# AE822FA0E5597LS0_CM55_HP_View register map
Vendor: Alif Semiconductor; Series: E8; File version: 1.0
CPU: CM55 r1p0, selectable endian, MPU, FPU, double-precision FPU, DSP, VTOR, 8 interrupt priority bits, 1 SAU regions
Registers are 32-bit, read-write, reset 0x0 unless marked. A register's access mark holds for its fields unless they carry their own. Offsets are from the block's base; [hi:lo] are bit positions; {n}, {i} and the like mark numbered series.

## JPEG
Base 0x49044000
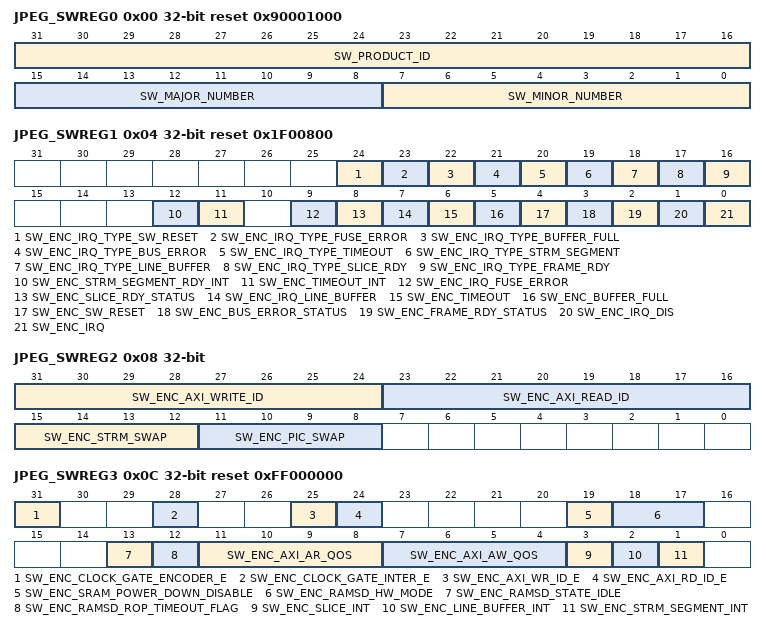
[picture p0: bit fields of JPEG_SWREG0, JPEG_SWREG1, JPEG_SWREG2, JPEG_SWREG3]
0x00 JPEG_SWREG0 ro reset 0x90001000 — ID register (read only)
  [31:16] SW_PRODUCT_ID — Product ID
  [15:8] SW_MAJOR_NUMBER — Major number
  [7:0] SW_MINOR_NUMBER — Minor number
0x04 JPEG_SWREG1 reset 0x1F00800 — Interrupt register encoder
  [24] SW_ENC_IRQ_TYPE_SW_RESET — IRQ type SW reset mask. 0=normal interruption. 1=abnormal interruption
  [23] SW_ENC_IRQ_TYPE_FUSE_ERROR — IRQ type fuse error mask. 0=normal interruption. 1=abnormal interruption
  [22] SW_ENC_IRQ_TYPE_BUFFER_FULL — IRQ type fuse buffer full mask. 0=normal interruption. 1=abnormal interruption
  [21] SW_ENC_IRQ_TYPE_BUS_ERROR — IRQ type bus error mask. 0=normal interruption. 1=abnormal interruption
  [20] SW_ENC_IRQ_TYPE_TIMEOUT — IRQ type timeout mask. 0=normal interruption. 1=abnormal interruption
  [19] SW_ENC_IRQ_TYPE_STRM_SEGMENT — IRQ type stream segment mask. 0=normal interruption. 1=abnormal interruption.
  [18] SW_ENC_IRQ_TYPE_LINE_BUFFER — IRQ type line buffer mask. 0=normal interruption. 1=abnormal interruption.
  [17] SW_ENC_IRQ_TYPE_SLICE_RDY — IRQ type slice ready mask. 0=normal interruption. 1=abnormal interruption.
  [16] SW_ENC_IRQ_TYPE_FRAME_RDY — IRQ type frame ready mask. 0=normal interruption. 1=abnormal interruption.
  [12] SW_ENC_STRM_SEGMENT_RDY_INT — Output stream segment IRQ. When high stream segment requests an interrupt. SW will reset this after interrupt is handled. It is clear by writing 1.
  [11] SW_ENC_TIMEOUT_INT — Enable timeout interrupt when 1
  [9] SW_ENC_IRQ_FUSE_ERROR — Interrupt status bit encoder. When this bit is high encoder has a FUSE error. SW try to setup feature but HW miss the feature set. It is clear by writing 1.
  [8] SW_ENC_SLICE_RDY_STATUS — Interrupt status bit encoder. When this bit is high encoder has encoded a slice. It is clear by writing 1.
  [7] SW_ENC_IRQ_LINE_BUFFER — Interrupt status bit encoder line buffer empty. When setting. Encoder has finished encoding input buffers. It is clear by writing 1.
  [6] SW_ENC_TIMEOUT — Interrupt status bit encoder timeout. When high the encoder has been idling for too long. Possible only if timeout interrupt is enabled. It is clear by writing 1.
  [5] SW_ENC_BUFFER_FULL — IRQ buffer full status bit. bufferFullInterrupt. It is clear by writing 1.
  [4] SW_ENC_SW_RESET — IRQ SW reset status bit. It is clear by writing 1.
  [3] SW_ENC_BUS_ERROR_STATUS — Interrupt status bit bus. Error response from bus. It is clear by writing 1.
  [2] SW_ENC_FRAME_RDY_STATUS — Interrupt status bit encoder. When this bit is high encoder has encoded a picture. It is clear by writing 1.
  [1] SW_ENC_IRQ_DIS — Encoder IRQ disable. When high there are no interrupts concerning encoder from HW. Polling must be used to see the interrupt statuses.
  [0] SW_ENC_IRQ — Encoder IRQ. When high encoder requests an interrupt. SW will reset this after interrupt is handled. It is clear by writing 1.
0x08 JPEG_SWREG2 — Data configuration register 0
  [31:24] SW_ENC_AXI_WRITE_ID — AXI Write ID
  [23:16] SW_ENC_AXI_READ_ID — AXI Read ID
  [15:12] SW_ENC_STRM_SWAP — Byte swap config for output stream data. 4-bit byte order vector to control byte locations inside HW internal 128 bit data vector. For 64 and 32 bit external bus widths the data is first gathered to 128 bit width and then bytes swapped accordingly.
  [11:8] SW_ENC_PIC_SWAP — Byte swap configuration for picture data (encoder input)
0x0C JPEG_SWREG3 reset 0xFF000000 — Data configuration register 1
  [31] SW_ENC_CLOCK_GATE_ENCODER_E — ASIC encoder clock gating control. 0=clock always on. 1=hardware clock gating control
  [28] SW_ENC_CLOCK_GATE_INTER_E — ASIC inter clock gating control. 0=clock always on. 1=hardware clock gating control
  [25] SW_ENC_AXI_WR_ID_E — AXI write enable. 0=disable. 1=enable.
  [24] SW_ENC_AXI_RD_ID_E — AXI read enable. 0=disable. 1=enable.
  [19] SW_ENC_SRAM_POWER_DOWN_DISABLE — SRAM power down mode disable
    1=SRAM power always on; 0=Go into power down mode when clock is gated
  [18:17] SW_ENC_RAMSD_HW_MODE — SRAM SD HW controlled mode
  [13] SW_ENC_RAMSD_STATE_IDLE ro — SRAM SD process idle state. 0=some srams are in the sd process. 1=all sram have completed sd process
  [12] SW_ENC_RAMSD_ROP_TIMEOUT_FLAG — Flags the timeout status of the sram SD_ROP signal. 0=the sram SD_ROP signal has not timed out. 1=the sram SD_ROP signal has timed out
  [11:8] SW_ENC_AXI_AR_QOS — AXI QoS identifier sent on the read address channel for read transaction
  [7:4] SW_ENC_AXI_AW_QOS — AXI QoS identifier sent on the write address channel for write transaction
  [3] SW_ENC_SLICE_INT — Enable slice interrupt when 1
  [2] SW_ENC_LINE_BUFFER_INT — Enable line buffer interrupt when 1
  [1] SW_ENC_STRM_SEGMENT_INT — Enable stream segment interrupt when 1
0x10 JPEG_SWREG4 — Control register 0
  [31:29] SW_ENC_MODE — Encoding mode. streamType. 3=AV1. 4=JPEG. Others=Reserved.
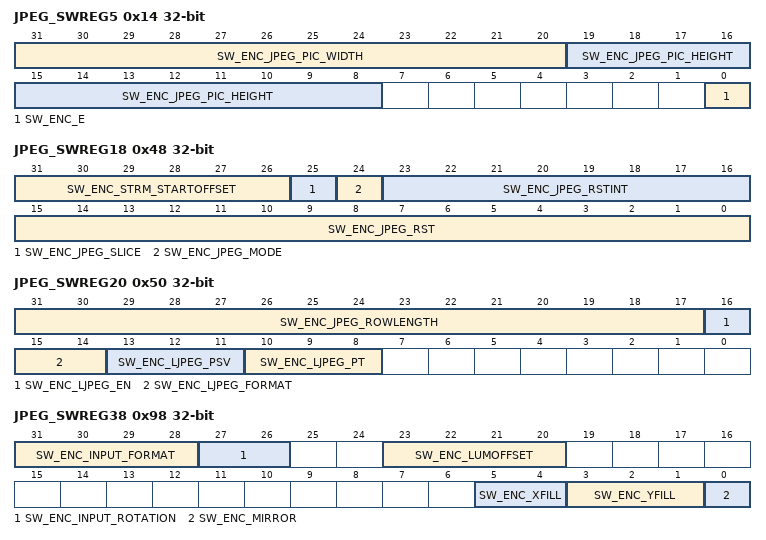
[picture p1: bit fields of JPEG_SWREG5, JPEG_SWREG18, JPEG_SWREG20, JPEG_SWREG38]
0x14 JPEG_SWREG5 — Control register 1
  [31:20] SW_ENC_JPEG_PIC_WIDTH — Encoded JPEG width. jpgLumWidth(unit 8 pixels)
  [19:8] SW_ENC_JPEG_PIC_HEIGHT — Encoded JPEG height. jpgLumHeight(unit 8 pixels): Max width x height is 16384 x 16384
  [0] SW_ENC_E — Encoder enable. Setting this bit high will start the encoding operation. HW will reset this when picture is processed or bus error or timeout interrupt is given.
0x20 JPEG_SWREG8 — Stream output buffer 0 address
  [31:0] SW_ENC_OUTPUT_STRM_BASE — stream output buffer0 base address
0x24 JPEG_SWREG9 — Stream output buffer 0 limit size
  [31:0] SW_ENC_OUTPUT_STRM_BUFFER_LIMIT — Stream buffer0 limit / Output stream size (bytes). If buffer0 limit is reached and sw_enc_HWStreamBufChain=0, buffer_full_IRQ will be generated. Output stream size will be updated here when a slice or frame is finished.
0x30 JPEG_SWREG12 — Input luma base address
  [31:0] SW_ENC_INPUT_Y_BASE — Input image luma base address
0x34 JPEG_SWREG13 — Input Cb base address
  [31:0] SW_ENC_INPUT_CB_BASE — Input image Cb base address
0x38 JPEG_SWREG14 — Input Cr base address
  [31:0] SW_ENC_INPUT_CR_BASE — Input image Cr base address
0x48 JPEG_SWREG18 — Reference picture reconstructed list 0 luma 0
  [31:26] SW_ENC_STRM_STARTOFFSET — Stream start offset = amount of StrmHdrRem (bits) [0..63]
  [25] SW_ENC_JPEG_SLICE — JPEG slice enable. 0=picture ends with EOI. 1=slice ends with RST
  [24] SW_ENC_JPEG_MODE — JPEG mode. 0=4:2:0 (4lum+2chr blocks/MCU). 1=4:2:2 (2lum+2chr blocks/MCU).
  [23:16] SW_ENC_JPEG_RSTINT — JPEG restart marker interval when slices are disabled (mb rows) [0..255]
  [15:0] SW_ENC_JPEG_RST — JPEG restart marker for first RST. incremented by HW for next RST
0x4C JPEG_SWREG19 — Reference picture reconstructed list 0 chroma 0
  [31:0] SW_ENC_STRM_HDRREM1 — Stream header remainder bits MSB (MSB aligned)
0x50 JPEG_SWREG20 — Reference picture reconstructed list 0 luma 1
  [31:17] SW_ENC_JPEG_ROWLENGTH — JPEG Input luminance row length. jpgLumWidthSrc (pixels) [96..16384]
  [16] SW_ENC_LJPEG_EN — JPEG enable lossless JPEG with Huffman coding
  [15:14] SW_ENC_LJPEG_FORMAT — JPEG Coding Mode. 0=420. 1=422. 2=luma only.
  [13:11] SW_ENC_LJPEG_PSV — JPEG prediction selection value for lossless
  [10:8] SW_ENC_LJPEG_PT — JPEG point transform value for lossless
0x54 JPEG_SWREG21 — Reference picture reconstructed list 0 chroma 1
  [31:0] SW_ENC_STRM_HDRREM2 — Stream header remainder bits LSB (MSB aligned)
0x94 JPEG_SWREG37 — SAO lambda parameter
  [3:0] SW_ENC_CHROFFSET — Input chrominance offset (bytes) [0..15]
0x98 JPEG_SWREG38 — Pre-processor configuration
  [31:28] SW_ENC_INPUT_FORMAT — Input image format. inputFormat. 0=YUV420P. 1=YUV420SP. 2=YUYV422. 3=UYVY422. Others=Reserved.
  [27:26] SW_ENC_INPUT_ROTATION — Input image rotation. 0=disabled. Others=Reserved.
  [23:20] SW_ENC_LUMOFFSET — Input luminance offset (bytes) [0..15]
  [5:4] SW_ENC_XFILL — Overfill pixels on right edge of image div2 [0.1.2.3]
  [3:1] SW_ENC_YFILL — Overfill pixels on bottom edge of image. YFill. [0...7]
  [0] SW_ENC_MIRROR — Mirror or not. [0.1]
0xB0 JPEG_SWREG44 — Pre-processor down-scaled configuration 1
  [1:0] SW_ENC_INPUT_FORMAT_MSB — Input image format bit[5:4]. inputFormatMsb.
0xB4 JPEG_SWREG45 — Pre-processor down-scaled configuration 2
  [27] SW_ENC_CHROMA_SWAP — Swap order of chroma bytes in semi planar input format.
0xD4 JPEG_SWREG53 — Input luma base address MSB
  [31:0] SW_ENC_INPUT_Y_BASE_MSB
0xD8 JPEG_SWREG54 — Input Cb base address MSB
  [31:0] SW_ENC_INPUT_CB_BASE_MSB
0xDC JPEG_SWREG55 — Input Cr base address MSB
  [31:0] SW_ENC_INPUT_CR_BASE_MSB
0xEC JPEG_SWREG59 — Stream output buffer 0 address MSB
  [31:0] SW_ENC_OUTPUT_STRM_BASE_MSB — Stream output buffer0 address MSB
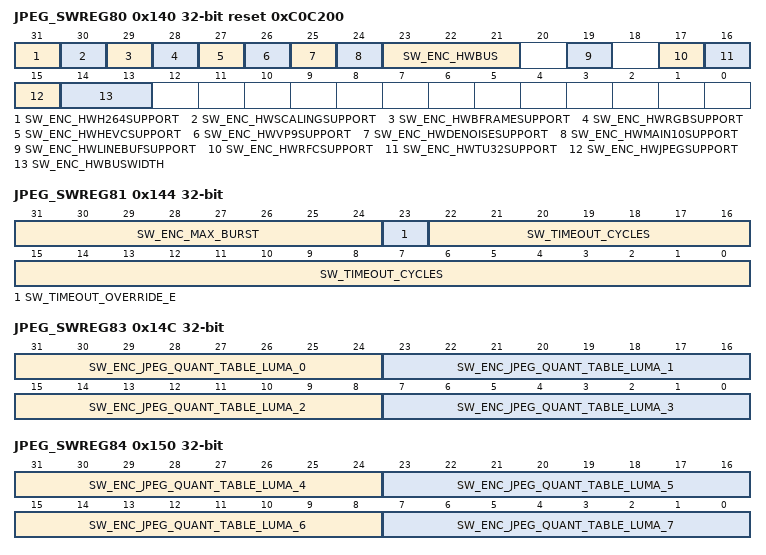
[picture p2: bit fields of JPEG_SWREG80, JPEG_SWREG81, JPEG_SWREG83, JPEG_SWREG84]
0x140 JPEG_SWREG80 ro reset 0xC0C200 — HW synthesis configuration register, read-only
  [31] SW_ENC_HWH264SUPPORT — H264 encoding supported by HW. 0=not supported.
  [30] SW_ENC_HWSCALINGSUPPORT — Down-scaling supported by HW. 0=not supported.
  [29] SW_ENC_HWBFRAMESUPPORT — HW bframe support. 0=not support bframe.
  [28] SW_ENC_HWRGBSUPPORT — RGB to YUV conversion supported by HW. 0=not supported.
  [27] SW_ENC_HWHEVCSUPPORT — HEVC encoding supported by HW. 0=not supported.
  [26] SW_ENC_HWVP9SUPPORT — VP9 encoding supported by HW. 0=not supported.
  [25] SW_ENC_HWDENOISESUPPORT — Denoise supported by HW. 0=not supported.
  [24] SW_ENC_HWMAIN10SUPPORT — Main profile supported by HW. 0=Main8 supported.
  [23:21] SW_ENC_HWBUS — Bus connection of HW. 6=AXIAPB.
  [19] SW_ENC_HWLINEBUFSUPPORT — LineBuffer input mode supported by HW. 0=not supported.
  [17] SW_ENC_HWRFCSUPPORT — Reference frame compression supported by HW. 0=not supported.
  [16] SW_ENC_HWTU32SUPPORT — TU32 supported by HW. 0=not supported.
  [15] SW_ENC_HWJPEGSUPPORT — JPEG encoder supported by HW.1=supported
  [14:13] SW_ENC_HWBUSWIDTH — Bus width of HW. 2=128b
0x144 JPEG_SWREG81 — Hardware configuration 0
  [31:24] SW_ENC_MAX_BURST — Maximum AXI burst length. Default value: 0x10
  [23] SW_TIMEOUT_OVERRIDE_E — Enable signal if timeout period is controlled by software. Default value: 0x0
  [22:0] SW_TIMEOUT_CYCLES — Timeout cycles number. Default value: 0x0
0x148 JPEG_SWREG82 — Record hardware performance
  [31:0] SW_ENC_HW_PERFORMANCE — Record hardware performance (cycles) of current picture
0x14C JPEG_SWREG83 — Reference picture reconstructed list 1 luma 0
  [31-8n:24-8n] SW_ENC_JPEG_QUANT_TABLE_LUMA_{n} (n=0..3) — JPEG quant table luma entry {n}
0x150 JPEG_SWREG84 — Reference picture reconstructed list 1 chroma 0
  [63-8n:56-8n] SW_ENC_JPEG_QUANT_TABLE_LUMA_{n} (n=4..7) — JPEG quant table luma entry {n}
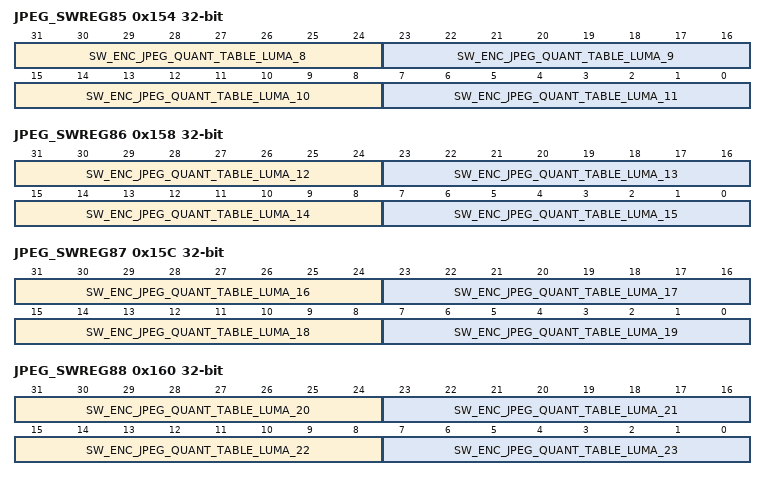
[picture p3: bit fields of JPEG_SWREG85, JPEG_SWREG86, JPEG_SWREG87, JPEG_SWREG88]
0x154 JPEG_SWREG85 — Reference picture reconstructed list 1 luma 1
  [95-8n:88-8n] SW_ENC_JPEG_QUANT_TABLE_LUMA_{n} (n=8..11) — JPEG quant table luma entry {n}
0x158 JPEG_SWREG86 — Reference picture reconstructed list 1 chroma 1
  [127-8n:120-8n] SW_ENC_JPEG_QUANT_TABLE_LUMA_{n} (n=12..15) — JPEG quant table luma entry {n}
0x15C JPEG_SWREG87 — Reference picture reconstructed list 1 luma 0 MSB
  [159-8n:152-8n] SW_ENC_JPEG_QUANT_TABLE_LUMA_{n} (n=16..19) — JPEG quant table luma entry {n}
0x160 JPEG_SWREG88 — Reference picture reconstructed list 1 chroma 0 MSB
  [191-8n:184-8n] SW_ENC_JPEG_QUANT_TABLE_LUMA_{n} (n=20..23) — JPEG quant table luma entry {n}
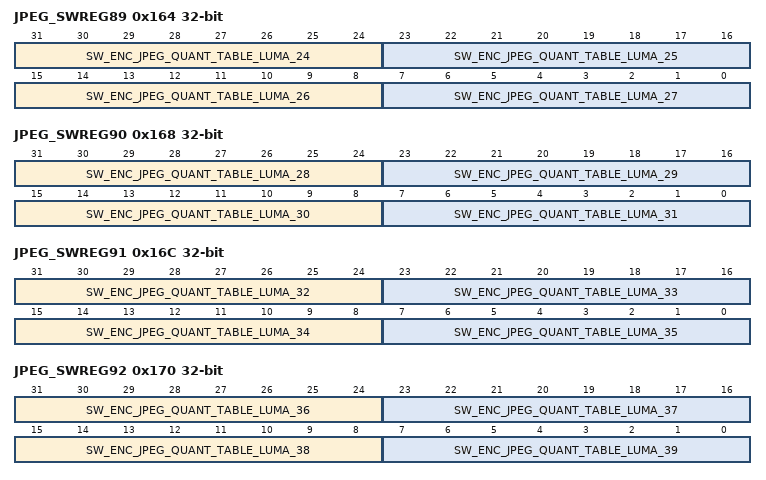
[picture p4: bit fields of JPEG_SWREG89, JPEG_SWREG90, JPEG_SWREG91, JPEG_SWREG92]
0x164 JPEG_SWREG89 — Reference picture reconstructed list 1 luma 1 MSB
  [223-8n:216-8n] SW_ENC_JPEG_QUANT_TABLE_LUMA_{n} (n=24..27) — JPEG quant table luma entry {n}
0x168 JPEG_SWREG90 — Reference picture reconstructed list 1 chroma 1 MSB
  [255-8n:248-8n] SW_ENC_JPEG_QUANT_TABLE_LUMA_{n} (n=28..31) — JPEG quant table luma entry {n}
0x16C JPEG_SWREG91 — Reference pictures list 1 configuration
  [287-8n:280-8n] SW_ENC_JPEG_QUANT_TABLE_LUMA_{n} (n=32..35) — JPEG quant table luma entry {n}
0x170 JPEG_SWREG92 — Reference picture reconstructed list 1 4n 0
  [319-8n:312-8n] SW_ENC_JPEG_QUANT_TABLE_LUMA_{n} (n=36..39) — JPEG quant table luma entry {n}
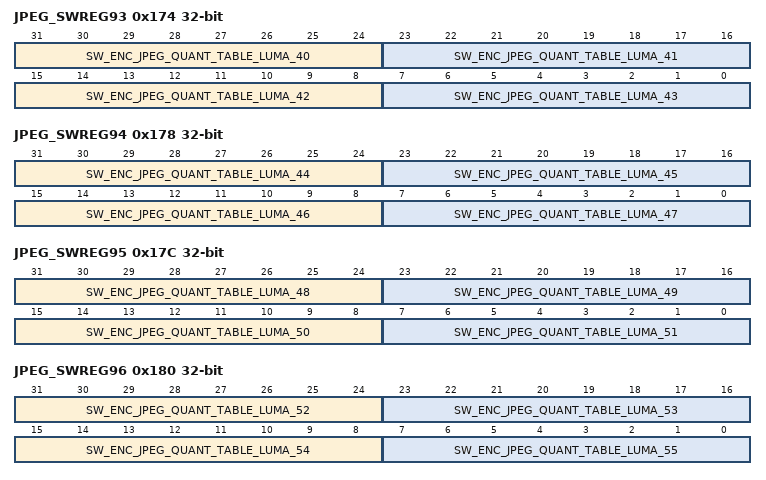
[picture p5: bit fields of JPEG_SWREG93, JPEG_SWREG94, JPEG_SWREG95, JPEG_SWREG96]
0x174 JPEG_SWREG93 — Reference picture reconstructed list 1 4n 0 MSB
  [351-8n:344-8n] SW_ENC_JPEG_QUANT_TABLE_LUMA_{n} (n=40..43) — JPEG quant table luma entry {n}
0x178 JPEG_SWREG94 — Reference picture reconstructed list 1 4n 1
  [383-8n:376-8n] SW_ENC_JPEG_QUANT_TABLE_LUMA_{n} (n=44..47) — JPEG quant table luma entry {n}
0x17C JPEG_SWREG95 — Reference picture reconstructed list 1 4n 1 MSB
  [415-8n:408-8n] SW_ENC_JPEG_QUANT_TABLE_LUMA_{n} (n=48..51) — JPEG quant table luma entry {n}
0x180 JPEG_SWREG96 — Base address for list 1 ref 0 luma compress table LSB
  [447-8n:440-8n] SW_ENC_JPEG_QUANT_TABLE_LUMA_{n} (n=52..55) — JPEG quant table luma entry {n}
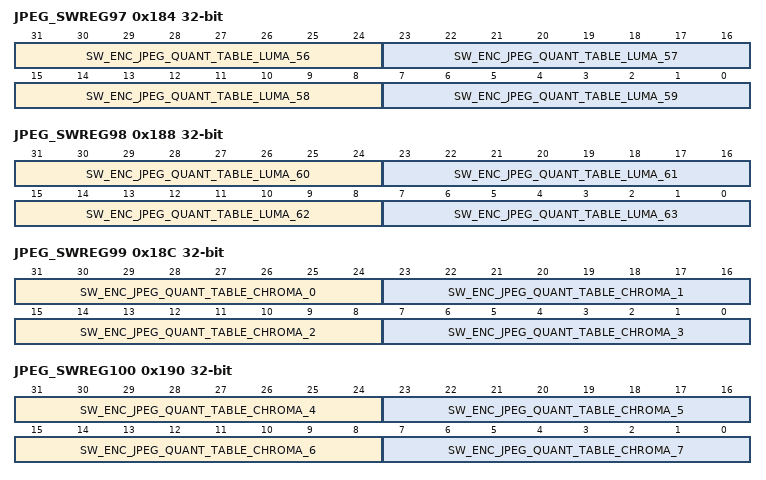
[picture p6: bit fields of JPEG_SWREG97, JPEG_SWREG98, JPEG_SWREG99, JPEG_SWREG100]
0x184 JPEG_SWREG97 — Base address for list 1 ref 0 luma compress table MSB
  [479-8n:472-8n] SW_ENC_JPEG_QUANT_TABLE_LUMA_{n} (n=56..59) — JPEG quant table luma entry {n}
0x188 JPEG_SWREG98 — Base address for list 1 ref 0 chroma compress table LSB
  [511-8n:504-8n] SW_ENC_JPEG_QUANT_TABLE_LUMA_{n} (n=60..63) — JPEG quant table luma entry {n}
0x18C JPEG_SWREG99 — Base address for list 1 ref 0 chroma compress table MSB
  [31-8n:24-8n] SW_ENC_JPEG_QUANT_TABLE_CHROMA_{n} (n=0..3) — JPEG quant table chroma entry {n}
0x190 JPEG_SWREG100 — Base address for list 1 ref 1 luma compress table LSB
  [63-8n:56-8n] SW_ENC_JPEG_QUANT_TABLE_CHROMA_{n} (n=4..7) — JPEG quant table chroma entry {n}
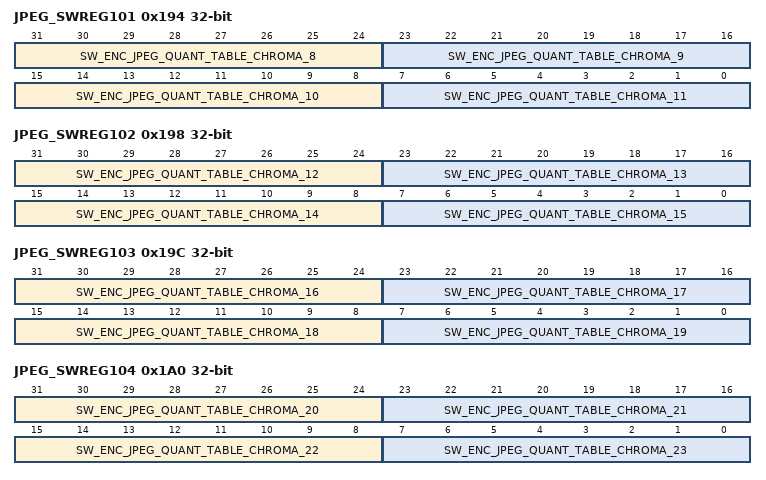
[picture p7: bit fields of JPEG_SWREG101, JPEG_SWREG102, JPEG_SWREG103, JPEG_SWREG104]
0x194 JPEG_SWREG101 — Base address for list 1 ref 1 luma compress table MSB
  [95-8n:88-8n] SW_ENC_JPEG_QUANT_TABLE_CHROMA_{n} (n=8..11) — JPEG quant table chroma entry {n}
0x198 JPEG_SWREG102 — Base address for list 1 ref 1 chroma compress table LSB
  [127-8n:120-8n] SW_ENC_JPEG_QUANT_TABLE_CHROMA_{n} (n=12..15) — JPEG quant table chroma entry {n}
0x19C JPEG_SWREG103 — Base address for list 1 ref 1 chroma compress table MSB
  [159-8n:152-8n] SW_ENC_JPEG_QUANT_TABLE_CHROMA_{n} (n=16..19) — JPEG quant table chroma entry {n}
0x1A0 JPEG_SWREG104 — Reference picture lists modification
  [191-8n:184-8n] SW_ENC_JPEG_QUANT_TABLE_CHROMA_{n} (n=20..23) — JPEG quant table chroma entry {n}
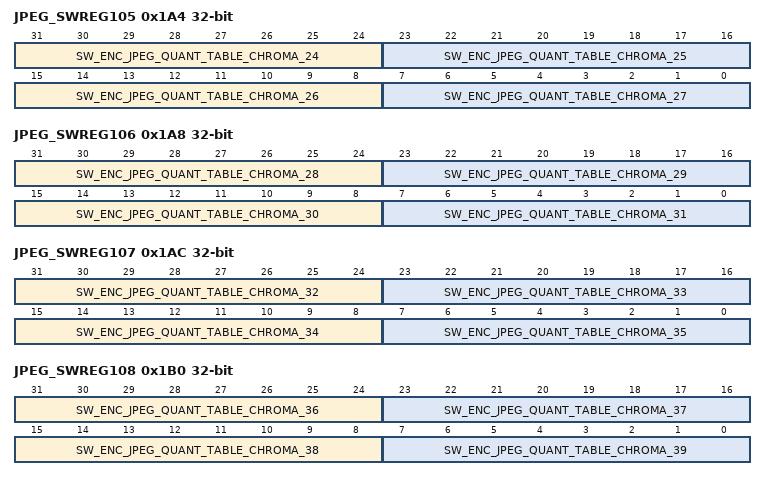
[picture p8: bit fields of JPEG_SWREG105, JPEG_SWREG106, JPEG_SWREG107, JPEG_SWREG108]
0x1A4 JPEG_SWREG105 — Target picture size
  [223-8n:216-8n] SW_ENC_JPEG_QUANT_TABLE_CHROMA_{n} (n=24..27) — JPEG quant table chroma entry {n}
0x1A8 JPEG_SWREG106 — Min picture size
  [255-8n:248-8n] SW_ENC_JPEG_QUANT_TABLE_CHROMA_{n} (n=28..31) — JPEG quant table chroma entry {n}
0x1AC JPEG_SWREG107 — Max picture size
  [287-8n:280-8n] SW_ENC_JPEG_QUANT_TABLE_CHROMA_{n} (n=32..35) — JPEG quant table chroma entry {n}
0x1B0 JPEG_SWREG108 — Average QP
  [319-8n:312-8n] SW_ENC_JPEG_QUANT_TABLE_CHROMA_{n} (n=36..39) — JPEG quant table chroma entry {n}
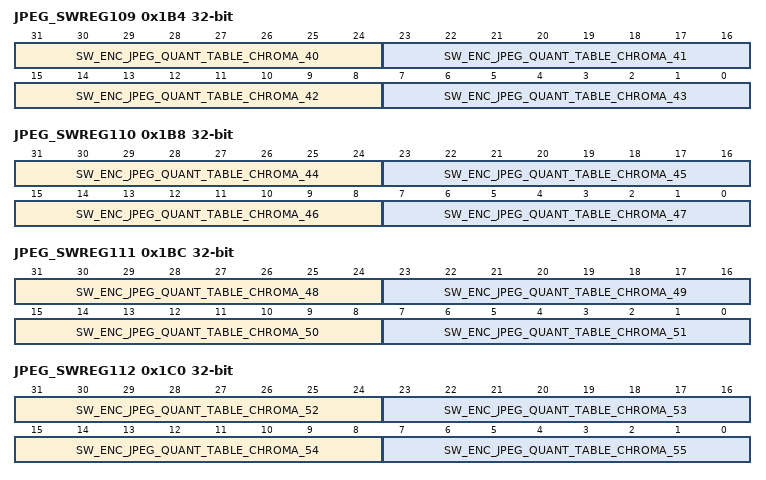
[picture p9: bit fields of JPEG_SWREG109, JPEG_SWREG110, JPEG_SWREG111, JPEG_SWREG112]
0x1B4 JPEG_SWREG109 — QP delta map
  [351-8n:344-8n] SW_ENC_JPEG_QUANT_TABLE_CHROMA_{n} (n=40..43) — JPEG quant table chroma entry {n}
0x1B8 JPEG_SWREG110 — QP delta map MSB
  [383-8n:376-8n] SW_ENC_JPEG_QUANT_TABLE_CHROMA_{n} (n=44..47) — JPEG quant table chroma entry {n}
0x1BC JPEG_SWREG111 — Adaptive GOP configuration 1
  [415-8n:408-8n] SW_ENC_JPEG_QUANT_TABLE_CHROMA_{n} (n=48..51) — JPEG quant table chroma entry {n}
0x1C0 JPEG_SWREG112 — Adaptive GOP configuration 2
  [447-8n:440-8n] SW_ENC_JPEG_QUANT_TABLE_CHROMA_{n} (n=52..55) — JPEG quant table chroma entry {n}
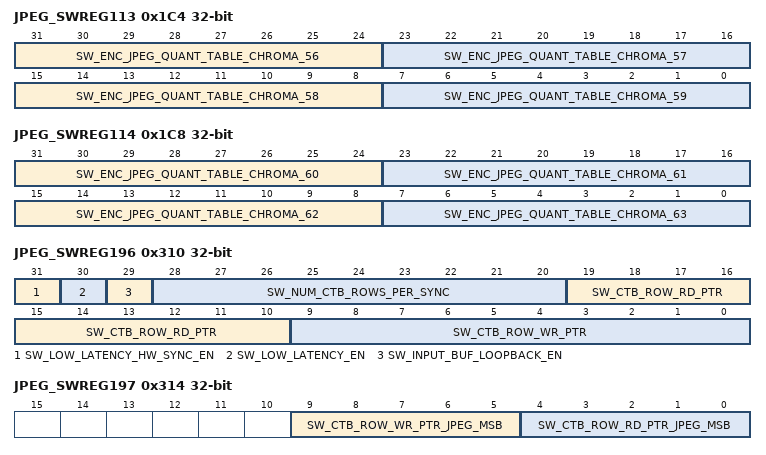
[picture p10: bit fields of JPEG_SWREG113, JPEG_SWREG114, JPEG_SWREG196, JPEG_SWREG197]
0x1C4 JPEG_SWREG113 — Adaptive GOP configuration 3
  [479-8n:472-8n] SW_ENC_JPEG_QUANT_TABLE_CHROMA_{n} (n=56..59) — JPEG quant table chroma entry {n}
0x1C8 JPEG_SWREG114 — CTB rate control bit memory address of current frame
  [511-8n:504-8n] SW_ENC_JPEG_QUANT_TABLE_CHROMA_{n} (n=60..63) — JPEG quant table chroma entry {n}
0x1FC JPEG_SWREG127 — Overlay 1 input luma buffer address
  [31:0] SW_ENC_OVERLAY_INPUT_YADDR1 — Overlay 1 input luma buffer address / OSDMap input buffer address
0x200 JPEG_SWREG128 — Overlay 1 input luma buffer address MSB part
  [31:0] SW_ENC_OVERLAY_INPUT_YADDR1_MSB — Overlay 1 input luma buffer address MSB part / OSDMap input buffer address MSB part
0x204 JPEG_SWREG129 — Overlay 1 input chroma U buffer address
  [31:0] SW_ENC_OVERLAY_INPUT_UADDR1
0x208 JPEG_SWREG130 — Overlay 1 input chroma U buffer address MSB part
  [31:0] SW_ENC_OVERLAY_INPUT_UADDR1_MSB
0x20C JPEG_SWREG131 — Overlay 1 input chroma V buffer address
  [31:0] SW_ENC_OVERLAY_INPUT_VADDR1
0x210 JPEG_SWREG132 — Overlay 1 input chroma V buffer address MSB part
  [31:0] SW_ENC_OVERLAY_INPUT_VADDR1_MSB
0x228 JPEG_SWREG138 — Overlay 2 input luma buffer address
  [31:0] SW_ENC_OVERLAY_INPUT_YADDR2
0x22C JPEG_SWREG139 — Overlay 2 input luma buffer address MSB part
  [31:0] SW_ENC_OVERLAY_INPUT_YADDR2_MSB
0x230 JPEG_SWREG140 — Overlay 2 input chroma U buffer address
  [31:0] SW_ENC_OVERLAY_INPUT_UADDR2
0x234 JPEG_SWREG141 — Overlay 2 input chroma U buffer address MSB part
  [31:0] SW_ENC_OVERLAY_INPUT_UADDR2_MSB
0x238 JPEG_SWREG142 — Overlay 2 input chroma V buffer address
  [31:0] SW_ENC_OVERLAY_INPUT_VADDR2
0x23C JPEG_SWREG143 — Overlay 2 input chroma V buffer address MSB part
  [31:0] SW_ENC_OVERLAY_INPUT_VADDR2_MSB
0x240 JPEG_SWREG144 — Overlay 3 input luma buffer address
  [31:0] SW_ENC_OVERLAY_INPUT_YADDR3
0x244 JPEG_SWREG145 — Overlay 3 input luma buffer address MSB part
  [31:0] SW_ENC_OVERLAY_INPUT_YADDR3_MSB
0x248 JPEG_SWREG146 — Overlay 3 input chroma U buffer address
  [31:0] SW_ENC_OVERLAY_INPUT_UADDR3
0x24C JPEG_SWREG147 — Overlay 3 input chroma U buffer address MSB part
  [31:0] SW_ENC_OVERLAY_INPUT_UADDR3_MSB
0x250 JPEG_SWREG148 — Overlay 3 input chroma V buffer address
  [31:0] SW_ENC_OVERLAY_INPUT_VADDR3
0x254 JPEG_SWREG149 — Overlay 3 input chroma V buffer address MSB part
  [31:0] SW_ENC_OVERLAY_INPUT_VADDR3_MSB
0x258 JPEG_SWREG150 — Overlay 4 input luma buffer address
  [31:0] SW_ENC_OVERLAY_INPUT_YADDR4
0x25C JPEG_SWREG151 — Overlay 4 input luma buffer address MSB part
  [31:0] SW_ENC_OVERLAY_INPUT_YADDR4_MSB
0x260 JPEG_SWREG152 — Overlay 4 input chroma U buffer address
  [31:0] SW_ENC_OVERLAY_INPUT_UADDR4
0x264 JPEG_SWREG153 — Overlay 4 input chroma U buffer address MSB part
  [31:0] SW_ENC_OVERLAY_INPUT_UADDR4_MSB
0x268 JPEG_SWREG154 — Overlay 4 input chroma V buffer address
  [31:0] SW_ENC_OVERLAY_INPUT_VADDR4
0x26C JPEG_SWREG155 — Overlay 4 input chroma V buffer address MSB part
  [31:0] SW_ENC_OVERLAY_INPUT_VADDR4_MSB
0x270 JPEG_SWREG156 — Overlay 5 input luma buffer address
  [31:0] SW_ENC_OVERLAY_INPUT_YADDR5
0x274 JPEG_SWREG157 — Overlay 5 input luma buffer address MSB part
  [31:0] SW_ENC_OVERLAY_INPUT_YADDR5_MSB
0x278 JPEG_SWREG158 — Overlay 5 input chroma U buffer address
  [31:0] SW_ENC_OVERLAY_INPUT_UADDR5
0x27C JPEG_SWREG159 — Overlay 5 input chroma U buffer address MSB part
  [31:0] SW_ENC_OVERLAY_INPUT_UADDR5_MSB
0x280 JPEG_SWREG160 — Overlay 5 input chroma V buffer address
  [31:0] SW_ENC_OVERLAY_INPUT_VADDR5
0x284 JPEG_SWREG161 — Overlay 5 input chroma V buffer address MSB part
  [31:0] SW_ENC_OVERLAY_INPUT_VADDR5_MSB
0x288 JPEG_SWREG162 — Overlay 6 input luma buffer address
  [31:0] SW_ENC_OVERLAY_INPUT_YADDR6
0x28C JPEG_SWREG163 — Overlay 6 input luma buffer address MSB part
  [31:0] SW_ENC_OVERLAY_INPUT_YADDR6_MSB
0x290 JPEG_SWREG164 — Overlay 6 input chroma U buffer address
  [31:0] SW_ENC_OVERLAY_INPUT_UADDR6
0x294 JPEG_SWREG165 — Overlay 6 input chroma U buffer address MSB part
  [31:0] SW_ENC_OVERLAY_INPUT_UADDR6_MSB
0x298 JPEG_SWREG166 — Overlay 6 input chroma V buffer address
  [31:0] SW_ENC_OVERLAY_INPUT_VADDR6
0x29C JPEG_SWREG167 — Overlay 6 input chroma V buffer address MSB part
  [31:0] SW_ENC_OVERLAY_INPUT_VADDR6_MSB
0x2A0 JPEG_SWREG168 — Overlay 7 input luma buffer address
  [31:0] SW_ENC_OVERLAY_INPUT_YADDR7
0x2A4 JPEG_SWREG169 — Overlay 7 input luma buffer address MSB part
  [31:0] SW_ENC_OVERLAY_INPUT_YADDR7_MSB
0x2B8 JPEG_SWREG174 — Overlay 7 input chroma U buffer address
  [31:0] SW_ENC_OVERLAY_INPUT_UADDR7
0x2BC JPEG_SWREG175 — Overlay 7 input chroma U buffer address MSB part
  [31:0] SW_ENC_OVERLAY_INPUT_UADDR7_MSB
0x2C0 JPEG_SWREG176 — Overlay 7 input chroma V buffer address
  [31:0] SW_ENC_OVERLAY_INPUT_VADDR7
0x2C4 JPEG_SWREG177 — Overlay 7 input chroma V buffer address MSB part
  [31:0] SW_ENC_OVERLAY_INPUT_VADDR7_MSB
0x2C8 JPEG_SWREG178 — Overlay 8 input luma buffer address
  [31:0] SW_ENC_OVERLAY_INPUT_YADDR8
0x2CC JPEG_SWREG179 — Overlay 8 input luma buffer address MSB part
  [31:0] SW_ENC_OVERLAY_INPUT_YADDR8_MSB
0x2D0 JPEG_SWREG180 — Overlay 8 input chroma U buffer address
  [31:0] SW_ENC_OVERLAY_INPUT_UADDR8
0x2E4 JPEG_SWREG185 — Picture complexity. Timeout cycles MSB.
  [8:0] SW_TIMEOUT_CYCLES_MSB — Extend swreg81. Timeout cycles number. Bits 31:23.
0x310 JPEG_SWREG196 — Low Latency Controls
  [31] SW_LOW_LATENCY_HW_SYNC_EN — Low Latency Hardware Interface Enable. Use hardware handshaking.
  [30] SW_LOW_LATENCY_EN — Low Latency Enable
  [29] SW_INPUT_BUF_LOOPBACK_EN — Input buffer loopback Enable
  [28:20] SW_NUM_CTB_ROWS_PER_SYNC — Number of CTB rows for every HW sync. Unit is CTB.
  [19:10] SW_CTB_ROW_RD_PTR — The number of CTB rows that has been fetched from Input buffer by encoder
  [9:0] SW_CTB_ROW_WR_PTR — The number of CTB rows that has been filled into the input buffer by external application
0x314 JPEG_SWREG197 — Delta POC extension
  [9:5] SW_CTB_ROW_WR_PTR_JPEG_MSB — msb of sw_ctb_row_wr_ptr for JPEG
  [4:0] SW_CTB_ROW_RD_PTR_JPEG_MSB — msb of sw_ctb_row_rd_ptr for JPEG
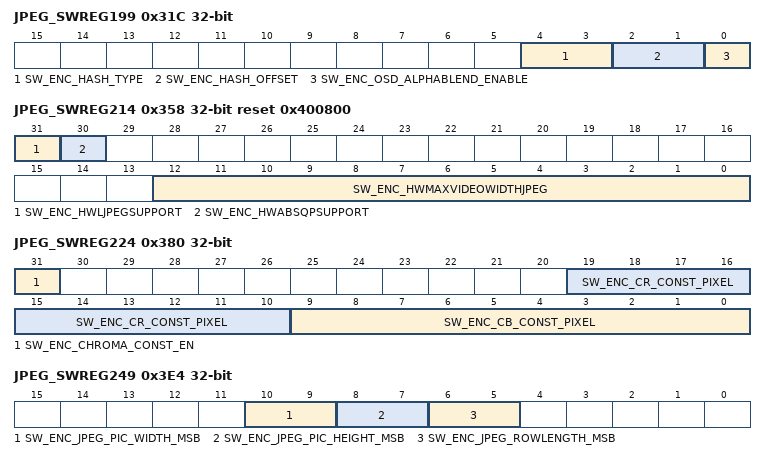
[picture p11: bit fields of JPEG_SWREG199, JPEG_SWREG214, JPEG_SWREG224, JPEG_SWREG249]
0x31C JPEG_SWREG199 — Hash Code Control
  [4:3] SW_ENC_HASH_TYPE — Hash type of frame data. 0=none. 1=crc32. 2=checksum32
  [2:1] SW_ENC_HASH_OFFSET — Hash offset (byte offset of processed hashdata)
  [0] SW_ENC_OSD_ALPHABLEND_ENABLE — Enable OSD Alpha Blending. 0=disable. 1=enable.
0x320 JPEG_SWREG200 — Hash Code Value
  [31:0] SW_ENC_HASH_VAL — Hash value of frame data
0x348 JPEG_SWREG210 — IPCM Control 1
  [31:12] SW_ENC_INPUT_LU_STRIDE — Luma stride of input frame
0x34C JPEG_SWREG211 — IPCM Control 2
  [31:12] SW_ENC_INPUT_CH_STRIDE — Chroma stride of input frame
0x358 JPEG_SWREG214 ro reset 0x400800 — HW synthesis configuration register 2, read-only
  [31] SW_ENC_HWLJPEGSUPPORT — Lossless JPEG supported by HW. 0=not supported.
  [30] SW_ENC_HWABSQPSUPPORT — Absolute QP in ROI/ROI map supported by HW. 0=not supported.
  [12:0] SW_ENC_HWMAXVIDEOWIDTHJPEG — Maximum video width supported by HW for JPEG encoding (unit 8 pixels)
0x35C JPEG_SWREG215 ro — AXI Information 0
  [31:0] SW_ENC_TOTALARLEN — [AXI] Accumulated ARLEN+1
0x360 JPEG_SWREG216 ro — AXI Information 1
  [31:0] SW_ENC_TOTALR — [AXI] RVALID & RREADY
0x364 JPEG_SWREG217 ro — AXI Information 2
  [31:0] SW_ENC_TOTALAR — [AXI] ARVALID & ARREADY
0x368 JPEG_SWREG218 ro — AXI Information 3
  [31:0] SW_ENC_TOTALRLAST — [AXI] RVALID & RREADY & RLAST
0x36C JPEG_SWREG219 ro — AXI Information 4
  [31:0] SW_ENC_TOTALAWLEN — [AXI] Accumulated AWLEN+1
0x370 JPEG_SWREG220 ro — AXI Information 5
  [31:0] SW_ENC_TOTALW — [AXI] WVALID & WREADY
0x374 JPEG_SWREG221 ro — AXI Information 6
  [31:0] SW_ENC_TOTALAW — [AXI] AWVALID & AWREADY
0x378 JPEG_SWREG222 ro — AXI Information 7
  [31:0] SW_ENC_TOTALWLAST — [AXI] WVALID & WREADY & WLAST
0x37C JPEG_SWREG223 ro — AXI Information 8
  [31:0] SW_ENC_TOTALB — [AXI] BVALID & BREADY
0x380 JPEG_SWREG224 — Control register 4
  [31] SW_ENC_CHROMA_CONST_EN — Force Chroma to be a constant pixel or not. 0=no. 1=yes.
  [19:10] SW_ENC_CR_CONST_PIXEL — The constant pixel of CR if bit SW_ENC_CHROMA_CONST_EN=1
  [9:0] SW_ENC_CB_CONST_PIXEL — The constant pixel of CB if bit SW_ENC_CHROMA_CONST_EN=1
0x388 JPEG_SWREG226 ro — HW synthesis configuration register 3, read-only
  [2] SW_ENC_HWSTREAMSEGMENTSUPPORT — Stream segment supported by HW. 0=not supported.
0x3D8 JPEG_SWREG246 — CTB RC Control 3
  [13:6] SW_ENC_AXI_WRITE_OUTSTANDING_NUM — AXI outstanding number of write operation
0x3E4 JPEG_SWREG249 — Register extension for 8K width
  [10:9] SW_ENC_JPEG_PIC_WIDTH_MSB — Encoded JPEG width. jpgLumWidthMSB(unit 8 pixels)
  [8:7] SW_ENC_JPEG_PIC_HEIGHT_MSB — Encoded JPEG height. jpgLumHeightMSB(unit 8 pixels): Max width x height is 24K x 24K
  [6:5] SW_ENC_JPEG_ROWLENGTH_MSB — JPEG Input luminance row length. jpgLumWidthSrcMSB (pixels) [96..16384]
0x414 JPEG_SWREG261 — Stride Control
  [11:4] SW_ENC_AXI_READ_OUTSTANDING_NUM — AXI outstanding number of read operation
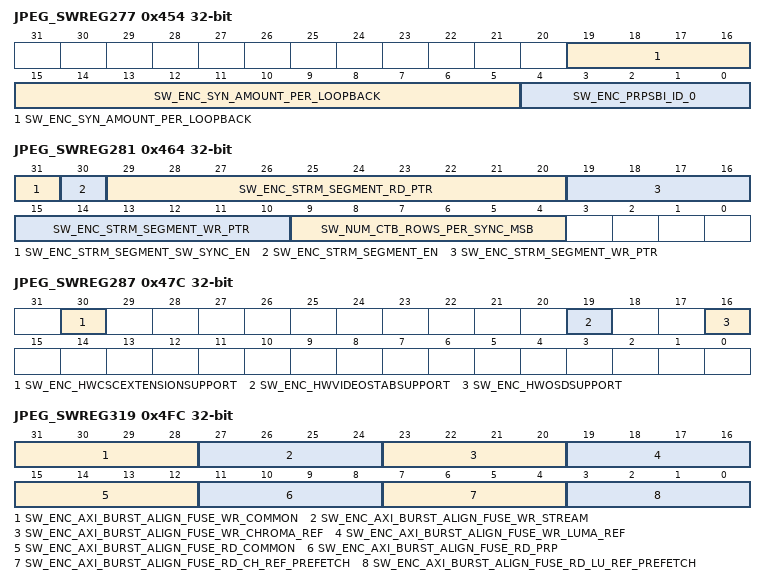
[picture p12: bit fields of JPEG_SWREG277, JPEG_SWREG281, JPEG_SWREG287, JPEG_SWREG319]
0x454 JPEG_SWREG277 — POC type/bits setting
  [19:5] SW_ENC_SYN_AMOUNT_PER_LOOPBACK — Handshake sync amount for every loopback
  [4:0] SW_ENC_PRPSBI_ID_0 — ID of prp sbi
0x458 JPEG_SWREG278 — Stream output buffer 1 address
  [31:0] SW_ENC_OUTPUT_STRM_BUF1_BASE — Stream output buffer1 base address. Only valid if sw_enc_HWStreamBufChain=1.
0x45C JPEG_SWREG279 — Stream output buffer 1 address MSB
  [31:0] SW_ENC_OUTPUT_STRM_BUF1_BASE_MSB — stream output buffer1 address MSB
0x460 JPEG_SWREG280 — Stream output buffer 1 limit size
  [31:0] SW_ENC_OUTPUT_STRM_BUFFER1_LIMIT — Stream buffer1 limit size (bytes). Only valid if sw_enc_HWStreamBufChain=1. If buffer1 limit is reached, buffer_full_IRQ will be generated.
0x464 JPEG_SWREG281 — POC type/bits setting
  [31] SW_ENC_STRM_SEGMENT_SW_SYNC_EN — Stream segment software handshake enable. Set 0 will disable this handshake
  [30] SW_ENC_STRM_SEGMENT_EN — Stream segment function enable
  [29:20] SW_ENC_STRM_SEGMENT_RD_PTR — The number of segments that have been read out from output buffer
  [19:10] SW_ENC_STRM_SEGMENT_WR_PTR — The number of segments that have been filled into the output buffer
  [9:4] SW_NUM_CTB_ROWS_PER_SYNC_MSB — Number MSB of CTB rows for every HW sync. Bit[14:9]. Unit is CTB.
0x47C JPEG_SWREG287 ro — HW synthesis configuration register 4, read-only
  [30] SW_ENC_HWCSCEXTENSIONSUPPORT — RGB to YUV conversion extension. 0=not supported.
  [19] SW_ENC_HWVIDEOSTABSUPPORT — HW supports video stabilization or not. 0=not supported.
  [16] SW_ENC_HWOSDSUPPORT — HW OSD supported by HW. 0=not supported.
0x480 JPEG_SWREG288 — Register fields extension
  [9:0] SW_ENC_PRPSBI_WRSEGINITNUM — Segment init num of prp sbi write before encoding a new frame
0x488 JPEG_SWREG290 ro — AXI2 Information 0
  [31:0] SW_ENC_TOTALARLEN2 — [AXI2] Accumulated ARLEN+1
0x48C JPEG_SWREG291 ro — AXI2 Information 1
  [31:0] SW_ENC_TOTALR2 — [AXI2] RVALID & RREADY
0x490 JPEG_SWREG292 ro — AXI2 Information 2
  [31:0] SW_ENC_TOTALAR2 — [AXI2] ARVALID & ARREADY
0x494 JPEG_SWREG293 ro — AXI2 Information 3
  [31:0] SW_ENC_TOTALRLAST2 — [AXI2] RVALID & RREADY & RLAST
0x498 JPEG_SWREG294 ro — AXI2 Information 4
  [31:0] SW_ENC_TOTALAWLEN2 — [AXI2] Accumulated AWLEN+1
0x49C JPEG_SWREG295 ro — AXI2 Information 5
  [31:0] SW_ENC_TOTALW2 — [AXI2] WVALID & WREADY
0x4A0 JPEG_SWREG296 ro — AXI2 Information 6
  [31:0] SW_ENC_TOTALAW2 — [AXI2] AWVALID & AWREADY
0x4A4 JPEG_SWREG297 ro — AXI2 Information 7
  [31:0] SW_ENC_TOTALWLAST2 — [AXI2] WVALID & WREADY & WLAST
0x4A8 JPEG_SWREG298 ro — AXI2 Information 8
  [31:0] SW_ENC_TOTALB2 — [AXI2] BVALID & BREADY
0x4D0 JPEG_SWREG308 ro — EMC stream AXI write pending
  [31:0] SW_ENC_AXI_STRM_WRITE_PENDING
0x4DC JPEG_SWREG311 ro — PRP AXI read pending
  [31:0] SW_ENC_AXI_PRP_READ_PENDING — Prp AXI read pending
0x4F4 JPEG_SWREG317 ro — Total AXI bus pending
  [31:0] SW_ENC_AXI_TOTAL_PENDING
0x4FC JPEG_SWREG319 ro — HW synthesis configuration register AXI
  [31:28] SW_ENC_AXI_BURST_ALIGN_FUSE_WR_COMMON — AXI burst align wr common fuse setting
  [27:24] SW_ENC_AXI_BURST_ALIGN_FUSE_WR_STREAM — AXI burst align wr stream fuse setting
  [23:20] SW_ENC_AXI_BURST_ALIGN_FUSE_WR_CHROMA_REF — AXI burst align wr chroma ref fuse setting
  [19:16] SW_ENC_AXI_BURST_ALIGN_FUSE_WR_LUMA_REF — AXI burst align wr luma ref fuse setting
  [15:12] SW_ENC_AXI_BURST_ALIGN_FUSE_RD_COMMON — AXI burst align rd common fuse setting
  [11:8] SW_ENC_AXI_BURST_ALIGN_FUSE_RD_PRP — AXI burst align rd prp fuse setting
  [7:4] SW_ENC_AXI_BURST_ALIGN_FUSE_RD_CH_REF_PREFETCH — AXI burst align rd ch ref prefetch fuse setting
  [3:0] SW_ENC_AXI_BURST_ALIGN_FUSE_RD_LU_REF_PREFETCH — AXI burst align rd lu ref prefetch fuse setting
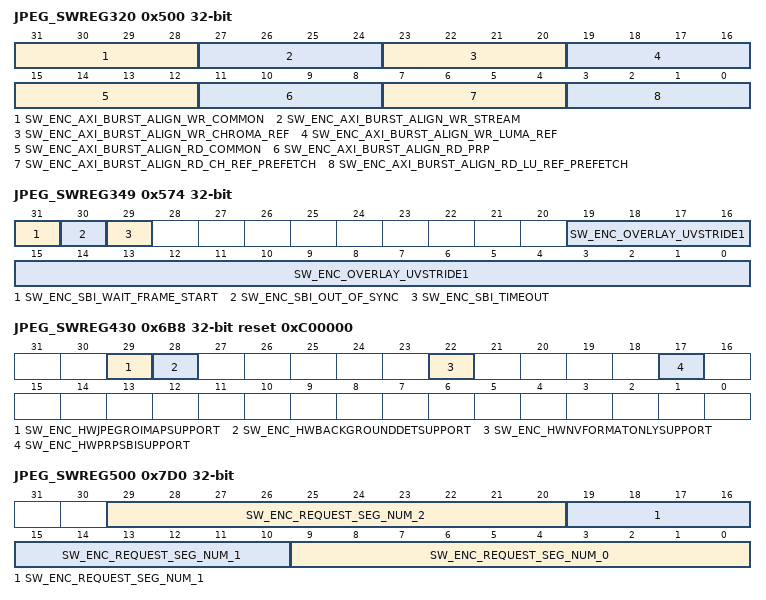
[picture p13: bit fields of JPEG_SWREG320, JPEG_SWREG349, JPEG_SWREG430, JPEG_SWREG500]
0x500 JPEG_SWREG320 — AXI alignment setting
  [31:28] SW_ENC_AXI_BURST_ALIGN_WR_COMMON — AXI burst align wr common
  [27:24] SW_ENC_AXI_BURST_ALIGN_WR_STREAM — AXI burst align wr stream
  [23:20] SW_ENC_AXI_BURST_ALIGN_WR_CHROMA_REF — AXI burst align wr chroma ref
  [19:16] SW_ENC_AXI_BURST_ALIGN_WR_LUMA_REF — AXI burst align wr luma ref
  [15:12] SW_ENC_AXI_BURST_ALIGN_RD_COMMON — AXI burst align rd common
  [11:8] SW_ENC_AXI_BURST_ALIGN_RD_PRP — AXI burst align rd prp
  [7:4] SW_ENC_AXI_BURST_ALIGN_RD_CH_REF_PREFETCH — AXI burst align rd ch ref prefetch
  [3:0] SW_ENC_AXI_BURST_ALIGN_RD_LU_REF_PREFETCH — AXI burst align rd lu ref prefetch
0x574 JPEG_SWREG349 — Overlay 1 chroma stride
  [31] SW_ENC_SBI_WAIT_FRAME_START — SBI wait for data ready before each frame start
  [30] SW_ENC_SBI_OUT_OF_SYNC — SBI out of sync indication bit
  [29] SW_ENC_SBI_TIMEOUT — SBI timeout indication bit
  [19:0] SW_ENC_OVERLAY_UVSTRIDE1 — Overlay 1 chroma stride
0x6B8 JPEG_SWREG430 ro reset 0xC00000 — HW synthesis configuration register 5, read-only
  [29] SW_ENC_HWJPEGROIMAPSUPPORT — HW Jpeg support Roi Map. 0=not supported.
  [28] SW_ENC_HWBACKGROUNDDETSUPPORT — HW Back ground detection support. 0=not supported.
  [22] SW_ENC_HWNVFORMATONLYSUPPORT — HW only support NV input format.1=only support NV input format
  [17] SW_ENC_HWPRPSBISUPPORT — PSNR calculation supported by HW. 0=not supported.
0x7D0 JPEG_SWREG500 ro — Flexa SBI. Enable dumping frame information to external memory.
  [29:20] SW_ENC_REQUEST_SEG_NUM_2 — seg num of successful handshaking request channel 2
  [19:10] SW_ENC_REQUEST_SEG_NUM_1 — seg num of successful handshaking request channel 1
  [9:0] SW_ENC_REQUEST_SEG_NUM_0 — seg num of successful handshaking request channel 0
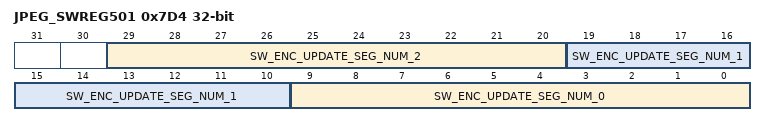
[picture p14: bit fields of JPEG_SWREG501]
0x7D4 JPEG_SWREG501 ro — Flexa SBI
  [29:20] SW_ENC_UPDATE_SEG_NUM_2 — seg num of successful handshaking update channel 2
  [19:10] SW_ENC_UPDATE_SEG_NUM_1 — seg num of successful handshaking update channel 1
  [9:0] SW_ENC_UPDATE_SEG_NUM_0 — seg num of successful handshaking update channel 0
0x7F4 JPEG_SWREG509 ro reset 0x2090 — Build ID
  [31:0] SW_ENC_BUILD_ID
0x7F8 JPEG_SWREG510 ro reset 0x1234567 — Build CL
  [31:0] SW_ENC_BUILD_CL
0x7FC JPEG_SWREG511 ro reset 0x20170420 — Build Date
  [31:0] SW_ENC_BUILD_DATE
